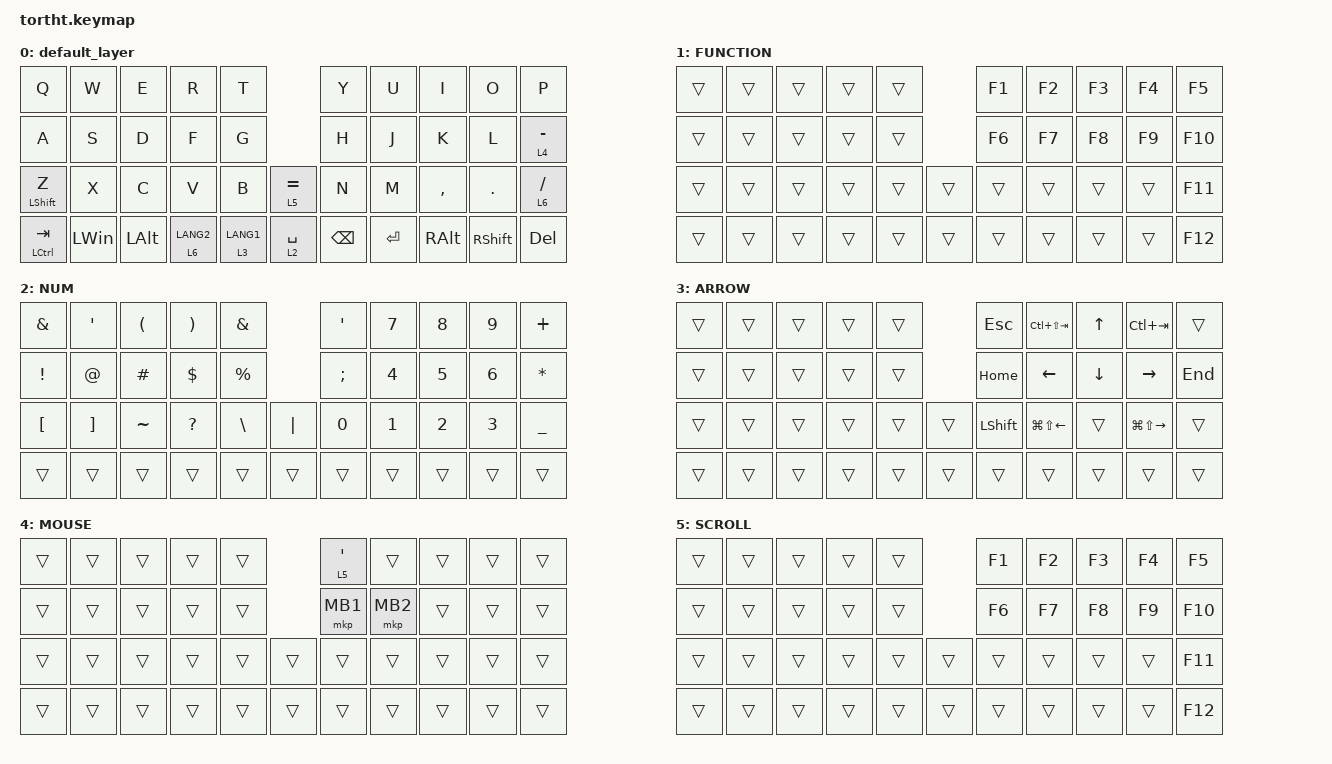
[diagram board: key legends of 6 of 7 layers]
#include <input/processors.dtsi>
#include <behaviors.dtsi>
#include <dt-bindings/zmk/bt.h>
#include <dt-bindings/zmk/keys.h>
#include <dt-bindings/zmk/pointing.h>

#define MOUSE 4
#define SCROLL 5
#define NUM 6




&mt {
    flavor = "balanced";
    quick-tap-ms = <0>;
};

&mkp_input_listener { input-processors = <&zip_temp_layer 4 250>; };

/ {
    macros {
        to_layer_0: to_layer_0 {
            compatible = "zmk,behavior-macro-one-param";
            #binding-cells = <1>;
            bindings = <&to 0 &macro_param_1to1 &kp MACRO_PLACEHOLDER>;
            label = "TO_LAYER_0";
        };

        exit_AML: exit_AML {
            compatible = "zmk,behavior-macro";
            wait-ms = <0>;
            tap-ms = <0>;
            #binding-cells = <0>;
            bindings = <&tog_off MOUSE>;
            label = "exit_AML";
        };

        kp_exit_AML: kp_exit_AML {
            compatible = "zmk,behavior-macro-one-param";
            wait-ms = <0>;
            tap-ms = <0>;
            #binding-cells = <1>;
            bindings = <&macro_param_1to1 &kp MACRO_PLACEHOLDER &exit_AML>;
            label = "KP_exit_AML";
        };
    };

    behaviors {
        lt_to_layer_0: lt_to_layer_0 {
            compatible = "zmk,behavior-hold-tap";
            label = "LAYER_TAP_TO_0";
            bindings = <&mo>, <&to_layer_0>;

            #binding-cells = <2>;
            tapping-term-ms = <200>;
        };

        tog_off: toggle_layer_off {
            compatible = "zmk,behavior-toggle-layer";
            #binding-cells = <1>;
            display-name = "Toggle Layer Off";
            toggle-mode = "off";
        };

        mt_exit_AML_on_tap: mt_exit_AML_on_tap {
            compatible = "zmk,behavior-hold-tap";
            label = "MT_exit_AML_ON_TAP";
            bindings = <&kp>, <&kp_exit_AML>;

            #binding-cells = <2>;
            tapping-term-ms = <200>;
            flavor = "balanced";
            quick-tap-ms = <200>;
        };
    };

    keymap {
        compatible = "zmk,keymap";

        default_layer {
            bindings = <
&kp Q             &kp W         &kp E         &kp R    &kp T                                                                         &kp Y          &kp U      &kp I      &kp O       &kp P
&kp A             &kp S         &kp D         &kp F    &kp G                                                                         &kp H          &kp J      &kp K      &kp L       &lt_to_layer_0 4 MINUS
&mt LEFT_SHIFT Z  &kp X         &kp C         &kp V    &kp B        &lt_to_layer_0 5 EQUAL                                           &kp N          &kp M      &kp COMMA  &kp DOT     &lt_to_layer_0 6 SLASH
&mt LCTRL TAB     &kp LEFT_WIN  &kp LEFT_ALT  &lt_to_layer_0 6 LANG2  &lt_to_layer_0 3 LANG1  &lt_to_layer_0 2 SPACE    &kp BACKSPACE  &kp ENTER  &kp RALT   &kp RSHIFT  &kp DEL
            >;
        };
        FUNCTION {
            bindings = <
&trans  &trans  &trans  &trans  &trans               &kp F1  &kp F2  &kp F3  &kp F4  &kp F5
&trans  &trans  &trans  &trans  &trans               &kp F6  &kp F7  &kp F8  &kp F9  &kp F10
&trans  &trans  &trans  &trans  &trans  &trans       &trans  &trans  &trans  &trans  &kp F11
&trans  &trans  &trans  &trans  &trans  &trans       &trans  &trans  &trans  &trans  &kp F12
            >;
        };

        NUM {
            bindings = <
&kp AMPERSAND     &kp SQT        &kp LPAR          &kp RPAR           &kp AMPS                           &kp SQT       &kp NUMBER_7  &kp NUMBER_8  &kp NUMBER_9  &kp PLUS
&kp EXCLAMATION   &kp AT         &kp HASH          &kp DOLLAR         &kp PERCENT                        &kp SEMI      &kp NUMBER_4  &kp NUMBER_5  &kp NUMBER_6  &kp ASTRK
&kp LBKT          &kp RBKT       &kp TILDE         &kp QMARK          &kp BSLH      &kp PIPE             &kp NUMBER_0  &kp NUMBER_1  &kp NUMBER_2  &kp NUMBER_3  &kp UNDER
&trans            &trans         &trans            &trans             &trans        &trans               &trans        &trans        &trans        &trans        &trans
            >;
        };

        ARROW {
            bindings = <
&trans  &trans  &trans  &trans  &trans                 &kp ESCAPE      &kp LC(LS(TAB))         &kp UP_ARROW    &kp LC(TAB)              &trans
&trans  &trans  &trans  &trans  &trans                 &kp HOME        &kp LEFT_ARROW          &kp DOWN_ARROW  &kp RIGHT_ARROW          &kp END
&trans  &trans  &trans  &trans  &trans   &trans        &kp LEFT_SHIFT  &kp LG(LS(LEFT_ARROW))  &trans          &kp LG(LS(RIGHT_ARROW))  &trans
&trans  &trans  &trans  &trans  &trans   &trans        &trans          &trans                  &trans          &trans                   &trans
            >;

            sensor-bindings = <&inc_dec_kp LC(PAGE_UP) LC(PAGE_DOWN)>;
        };

        MOUSE {
            bindings = <
&trans  &trans  &trans  &trans  &trans              &lt_to_layer_0 5 SQT &trans     &trans    &trans    &trans
&trans  &trans  &trans  &trans  &trans              &mkp MB1             &mkp MB2   &trans    &trans    &trans
&trans  &trans  &trans  &trans  &trans  &trans      &trans               &trans     &trans    &trans    &trans
&trans  &trans  &trans  &trans  &trans  &trans      &trans               &trans     &trans    &trans    &trans
            >;
        };

        SCROLL {
            bindings = <
&trans  &trans  &trans  &trans  &trans              &kp F1  &kp F2  &kp F3  &kp F4  &kp F5
&trans  &trans  &trans  &trans  &trans              &kp F6  &kp F7  &kp F8  &kp F9  &kp F10
&trans  &trans  &trans  &trans  &trans  &trans      &trans  &trans  &trans  &trans  &kp F11
&trans  &trans  &trans  &trans  &trans  &trans      &trans  &trans  &trans  &trans  &kp F12
            >;
        };

        layer_6 {
            bindings = <
&trans  &trans        &trans        &trans        &trans                             &bt BT_SEL 0  &bt BT_SEL 1  &bt BT_SEL 2  &bt BT_SEL 3  &bt BT_SEL 4
&trans  &trans        &trans        &trans        &trans  &trans                     &trans        &trans        &trans        &trans        &trans
&trans  &kp NUMBER_1  &kp NUMBER_2  &kp NUMBER_3  &trans  &trans      &bootloader    &trans        &trans        &trans        &trans        &bt BT_CLR
&trans  &trans        &trans        &trans        &trans  &trans      &trans         &trans        &trans        &trans        &trans        &bt BT_CLR_ALL
            >;
        };
    };
};

